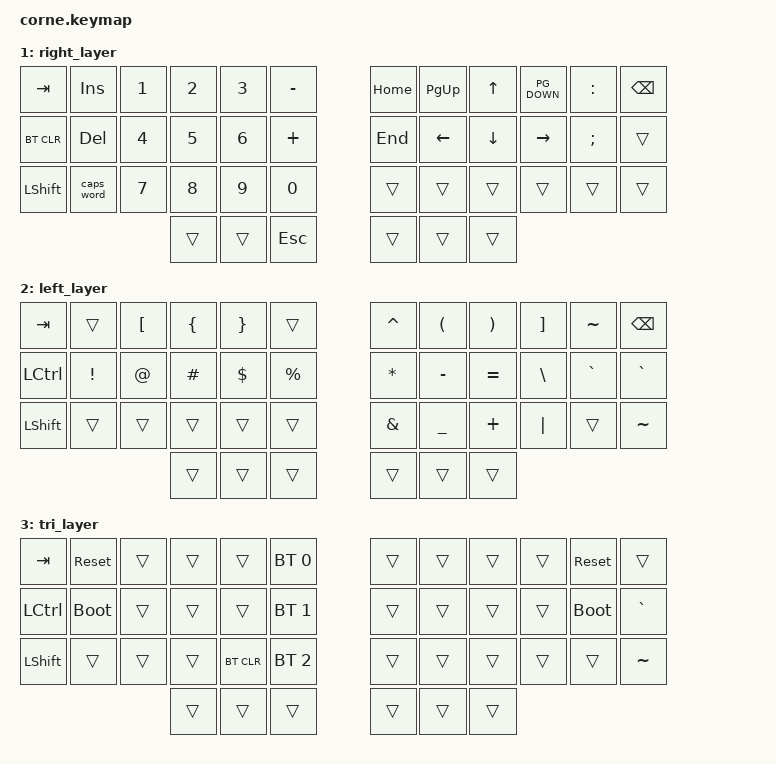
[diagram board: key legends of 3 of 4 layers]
/*
 * Copyright (c) 2020 The ZMK Contributors
 *
 * SPDX-License-Identifier: MIT
 */

#include <behaviors.dtsi>
#include <dt-bindings/zmk/keys.h>
#include <dt-bindings/zmk/bt.h>

// Home row mods macro
#define HRML(k1,k2,k3,k4) &ht LSHFT k1  &ht LALT k2  &ht LCTRL k3  &ht LGUI k4
#define HRMR(k1,k2,k3,k4) &ht RGUI k1  &ht RCTRL k2  &ht RALT k3  &ht RSHFT k4

/ {
    behaviors {
        ht: hold_tap {
            compatible = "zmk,behavior-hold-tap";
            #binding-cells = <2>;
            flavor = "tap-preferred";
            tapping-term-ms = <220>;
            quick-tap-ms = <150>;
            require-prior-idle-ms = <100>;
            bindings = <&kp>, <&kp>;
        };
    };

    conditional_layers {
        compatible = "zmk,conditional-layers";
        tri_layer {
            if-layers = <1 2>;
            then-layer = <3>;
        };
    };

/ {
        keymap {
                compatible = "zmk,keymap";

                default_layer {
                        bindings = <
   &kp TAB   &kp Q &kp W &kp E &kp R &kp T   &kp Y &kp U  &kp I     &kp O   &kp P    &kp BSPC
   &kp LCTRL HMRL(A, S, D, &kp F) &kp G   &kp H HRMR(J,   K,     L,   SQT) &kp SQT
   &kp LSHFT &kp Z &kp X &kp C &kp V &kp B   &kp N &kp M  &kp COMMA &kp DOT &kp FSLH &kp ESC
                  &kp DELETE &lt 2 TAB &kp SPACE   &kp RET &lt 1 &kp C_MUTE
                        >;
                        };
                right_layer {
                        bindings = <
   &kp TAB &kp INSERT    &kp N1       &kp N2       &kp N3       &kp MINUS       &kp HOME         &kp PG_UP   &kp UP   &kp PG_DOWN &kp COLON &kp BSPC
   &bt BT_CLR &kp DELETE &kp N4 &kp N5 &kp N6 &kp PLUS &kp END   &kp LEFT &kp DOWN &kp RIGHT &kp SEMI &trans
   &kp LSHFT  &caps_word &kp N7       &kp N8       &kp N9       &kp N0       &trans         &trans   &trans   &trans &trans    &trans
                                    &trans     &trans       &kp ESC      &trans  &trans   &trans
                        >;
                        };

                left_layer {
                        bindings = <
   &kp  TAB  &trans &kp LBKT &kp LBRC &kp RBRC &trans   &kp CARET &kp LPAR  &kp RPAR &kp RBKT &kp TILDE &kp BSPC
   &kp LCTRL &kp EXCL   &kp AT &kp HASH   &kp DLLR &kp PRCNT      &kp ASTRK &kp MINUS &kp EQUAL  &kp BSLH &kp GRAVE &kp GRAVE
   &kp LSHFT &trans   &trans &trans   &trans   &trans      &kp AMPS &kp UNDER  &kp PLUS  &kp PIPE &trans &kp TILDE
                             &trans &trans   &trans   &trans   &trans    &trans
                        >;
                        };
                tri_layer {
                        bindings = <
   &kp  TAB  &sys_reset &trans &trans &trans &bt BT_SEL 0  &trans &trans  &trans &trans &sys_reset &trans
   &kp LCTRL &bootloader   &trans &trans &trans  &bt BT_SEL 1      &trans &trans &trans  &trans &bootloader &kp GRAVE
   &kp LSHFT &trans   &trans &trans   &bt BT_CLR   &bt BT_SEL 2      &trans &trans  &trans  &trans &trans &kp TILDE
                             &trans &trans   &trans   &trans   &trans    &trans
                        >;
                        };
                };
        };
};
